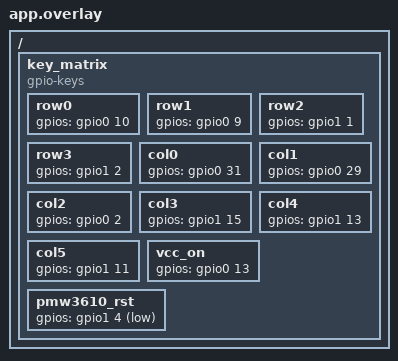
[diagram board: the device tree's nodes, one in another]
/ {
    key_matrix {
        compatible = "gpio-keys";
        status = "okay";

        row0: row0 {
            gpios = <&gpio0 10 GPIO_ACTIVE_HIGH>;
        };
        row1: row1 {
            gpios = <&gpio0 9 GPIO_ACTIVE_HIGH>;
        };
        row2: row2 {
            gpios = <&gpio1 1 GPIO_ACTIVE_HIGH>;
        };
        row3: row3 {
            gpios = <&gpio1 2 GPIO_ACTIVE_HIGH>;
        };
        col0: col0 {
            gpios = <&gpio0 31 GPIO_ACTIVE_HIGH>;
        };
        col1: col1 {
            gpios = <&gpio0 29 GPIO_ACTIVE_HIGH>;
        };
        col2: col2 {
            gpios = <&gpio0 2 GPIO_ACTIVE_HIGH>;
        };
        col3: col3 {
            gpios = <&gpio1 15 GPIO_ACTIVE_HIGH>;
        };
        col4: col4 {
            gpios = <&gpio1 13 GPIO_ACTIVE_HIGH>;
        };
        col5: col5 {
            gpios = <&gpio1 11 GPIO_ACTIVE_HIGH>;
        };
        vcc_on: vcc_on {
            gpios = <&gpio0 13 GPIO_ACTIVE_HIGH>;
        };

        pmw3610_rst: pmw3610_rst {
            gpios = <&gpio1 4 GPIO_ACTIVE_LOW>;
        };
    };
};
